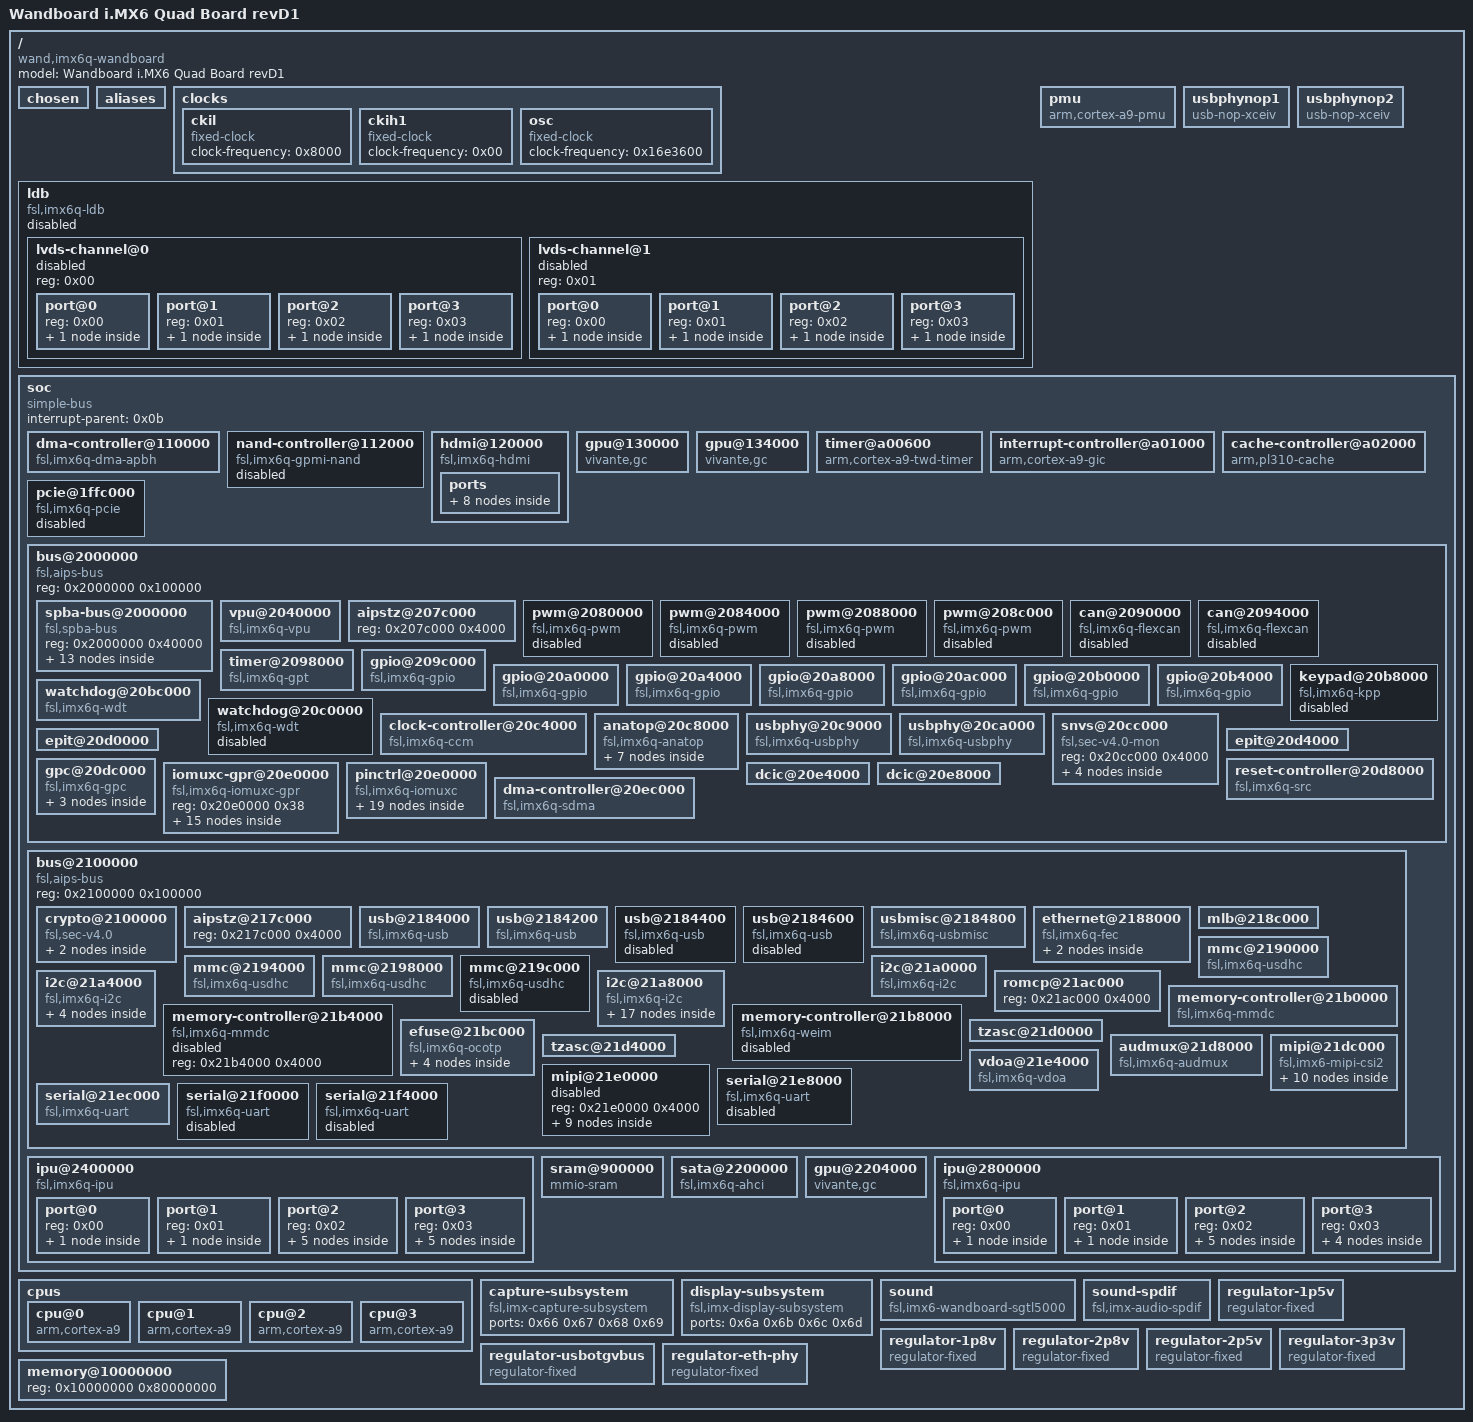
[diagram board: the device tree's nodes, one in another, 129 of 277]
/*
 * Copyright Linux Kernel Team
 *
 * SPDX-License-Identifier: GPL-2.0-only
 *
 * This file is derived from an intermediate build stage of the
 * Linux kernel. The licenses of all input files to this process
 * are compatible with GPL-2.0-only.
 */

/dts-v1/;

/ {
	#address-cells = <0x01>;
	#size-cells = <0x01>;
	model = "Wandboard i.MX6 Quad Board revD1";
	compatible = "wand,imx6q-wandboard", "fsl,imx6q";

	chosen {
		stdout-path = "/soc/bus@2000000/spba-bus@2000000/serial@2020000";
	};

	aliases {
		ethernet0 = "/soc/bus@2100000/ethernet@2188000";
		can0 = "/soc/bus@2000000/can@2090000";
		can1 = "/soc/bus@2000000/can@2094000";
		gpio0 = "/soc/bus@2000000/gpio@209c000";
		gpio1 = "/soc/bus@2000000/gpio@20a0000";
		gpio2 = "/soc/bus@2000000/gpio@20a4000";
		gpio3 = "/soc/bus@2000000/gpio@20a8000";
		gpio4 = "/soc/bus@2000000/gpio@20ac000";
		gpio5 = "/soc/bus@2000000/gpio@20b0000";
		gpio6 = "/soc/bus@2000000/gpio@20b4000";
		i2c0 = "/soc/bus@2100000/i2c@21a0000";
		i2c1 = "/soc/bus@2100000/i2c@21a4000";
		i2c2 = "/soc/bus@2100000/i2c@21a8000";
		ipu0 = "/soc/ipu@2400000";
		mmc0 = "/soc/bus@2100000/mmc@2190000";
		mmc1 = "/soc/bus@2100000/mmc@2194000";
		mmc2 = "/soc/bus@2100000/mmc@2198000";
		mmc3 = "/soc/bus@2100000/mmc@219c000";
		serial0 = "/soc/bus@2000000/spba-bus@2000000/serial@2020000";
		serial1 = "/soc/bus@2100000/serial@21e8000";
		serial2 = "/soc/bus@2100000/serial@21ec000";
		serial3 = "/soc/bus@2100000/serial@21f0000";
		serial4 = "/soc/bus@2100000/serial@21f4000";
		spi0 = "/soc/bus@2000000/spba-bus@2000000/spi@2008000";
		spi1 = "/soc/bus@2000000/spba-bus@2000000/spi@200c000";
		spi2 = "/soc/bus@2000000/spba-bus@2000000/spi@2010000";
		spi3 = "/soc/bus@2000000/spba-bus@2000000/spi@2014000";
		usb0 = "/soc/bus@2100000/usb@2184000";
		usb1 = "/soc/bus@2100000/usb@2184200";
		usb2 = "/soc/bus@2100000/usb@2184400";
		usb3 = "/soc/bus@2100000/usb@2184600";
		usbphy0 = "/soc/bus@2000000/usbphy@20c9000";
		usbphy1 = "/soc/bus@2000000/usbphy@20ca000";
		ipu1 = "/soc/ipu@2800000";
		spi4 = "/soc/bus@2000000/spba-bus@2000000/spi@2018000";
	};

	clocks {

		ckil {
			compatible = "fixed-clock";
			#clock-cells = <0x00>;
			clock-frequency = <0x8000>;
		};

		ckih1 {
			compatible = "fixed-clock";
			#clock-cells = <0x00>;
			clock-frequency = <0x00>;
		};

		osc {
			compatible = "fixed-clock";
			#clock-cells = <0x00>;
			clock-frequency = <0x16e3600>;
		};
	};

	ldb {
		#address-cells = <0x01>;
		#size-cells = <0x00>;
		compatible = "fsl,imx6q-ldb", "fsl,imx53-ldb";
		gpr = <0x01>;
		status = "disabled";
		clocks = <0x02 0x21 0x02 0x22 0x02 0x27 0x02 0x28 0x02 0x29 0x02 0x2a 0x02 0x87 0x02 0x88>;
		clock-names = "di0_pll", "di1_pll", "di0_sel", "di1_sel", "di2_sel", "di3_sel", "di0", "di1";

		lvds-channel@0 {
			#address-cells = <0x01>;
			#size-cells = <0x00>;
			reg = <0x00>;
			status = "disabled";

			port@0 {
				reg = <0x00>;

				endpoint {
					remote-endpoint = <0x03>;
					phandle = <0x52>;
				};
			};

			port@1 {
				reg = <0x01>;

				endpoint {
					remote-endpoint = <0x04>;
					phandle = <0x56>;
				};
			};

			port@2 {
				reg = <0x02>;

				endpoint {
					remote-endpoint = <0x05>;
					phandle = <0x5c>;
				};
			};

			port@3 {
				reg = <0x03>;

				endpoint {
					remote-endpoint = <0x06>;
					phandle = <0x60>;
				};
			};
		};

		lvds-channel@1 {
			#address-cells = <0x01>;
			#size-cells = <0x00>;
			reg = <0x01>;
			status = "disabled";

			port@0 {
				reg = <0x00>;

				endpoint {
					remote-endpoint = <0x07>;
					phandle = <0x53>;
				};
			};

			port@1 {
				reg = <0x01>;

				endpoint {
					remote-endpoint = <0x08>;
					phandle = <0x57>;
				};
			};

			port@2 {
				reg = <0x02>;

				endpoint {
					remote-endpoint = <0x09>;
					phandle = <0x5d>;
				};
			};

			port@3 {
				reg = <0x03>;

				endpoint {
					remote-endpoint = <0x0a>;
					phandle = <0x61>;
				};
			};
		};
	};

	pmu {
		compatible = "arm,cortex-a9-pmu";
		interrupt-parent = <0x0b>;
		interrupts = <0x00 0x5e 0x04>;
	};

	usbphynop1 {
		compatible = "usb-nop-xceiv";
		#phy-cells = <0x00>;
		phandle = <0x2a>;
	};

	usbphynop2 {
		compatible = "usb-nop-xceiv";
		#phy-cells = <0x00>;
		phandle = <0x2b>;
	};

	soc {
		#address-cells = <0x01>;
		#size-cells = <0x01>;
		compatible = "simple-bus";
		interrupt-parent = <0x0b>;
		ranges;

		dma-controller@110000 {
			compatible = "fsl,imx6q-dma-apbh", "fsl,imx28-dma-apbh";
			reg = <0x110000 0x2000>;
			interrupts = <0x00 0x0d 0x04 0x00 0x0d 0x04 0x00 0x0d 0x04 0x00 0x0d 0x04>;
			#dma-cells = <0x01>;
			dma-channels = <0x04>;
			clocks = <0x02 0x6a>;
			phandle = <0x0c>;
		};

		nand-controller@112000 {
			compatible = "fsl,imx6q-gpmi-nand";
			reg = <0x112000 0x2000 0x114000 0x2000>;
			reg-names = "gpmi-nand", "bch";
			interrupts = <0x00 0x0f 0x04>;
			interrupt-names = "bch";
			clocks = <0x02 0x98 0x02 0x99 0x02 0x97 0x02 0x96 0x02 0x95>;
			clock-names = "gpmi_io", "gpmi_apb", "gpmi_bch", "gpmi_bch_apb", "per1_bch";
			dmas = <0x0c 0x00>;
			dma-names = "rx-tx";
			status = "disabled";
		};

		hdmi@120000 {
			reg = <0x120000 0x9000>;
			interrupts = <0x00 0x73 0x04>;
			gpr = <0x01>;
			clocks = <0x02 0x7b 0x02 0x7c>;
			clock-names = "iahb", "isfr";
			status = "okay";
			compatible = "fsl,imx6q-hdmi";
			ddc-i2c-bus = <0x0d>;

			ports {
				#address-cells = <0x01>;
				#size-cells = <0x00>;

				port@0 {
					reg = <0x00>;

					endpoint {
						remote-endpoint = <0x0e>;
						phandle = <0x50>;
					};
				};

				port@1 {
					reg = <0x01>;

					endpoint {
						remote-endpoint = <0x0f>;
						phandle = <0x54>;
					};
				};

				port@2 {
					reg = <0x02>;

					endpoint {
						remote-endpoint = <0x10>;
						phandle = <0x5a>;
					};
				};

				port@3 {
					reg = <0x03>;

					endpoint {
						remote-endpoint = <0x11>;
						phandle = <0x5e>;
					};
				};
			};
		};

		gpu@130000 {
			compatible = "vivante,gc";
			reg = <0x130000 0x4000>;
			interrupts = <0x00 0x09 0x04>;
			clocks = <0x02 0x1b 0x02 0x7a 0x02 0x4a>;
			clock-names = "bus", "core", "shader";
			power-domains = <0x12>;
			#cooling-cells = <0x02>;
		};

		gpu@134000 {
			compatible = "vivante,gc";
			reg = <0x134000 0x4000>;
			interrupts = <0x00 0x0a 0x04>;
			clocks = <0x02 0x1a 0x02 0x79>;
			clock-names = "bus", "core";
			power-domains = <0x12>;
			#cooling-cells = <0x02>;
		};

		timer@a00600 {
			compatible = "arm,cortex-a9-twd-timer";
			reg = <0xa00600 0x20>;
			interrupts = <0x01 0x0d 0xf01>;
			interrupt-parent = <0x13>;
			clocks = <0x02 0x0f>;
		};

		interrupt-controller@a01000 {
			compatible = "arm,cortex-a9-gic";
			#interrupt-cells = <0x03>;
			interrupt-controller;
			reg = <0xa01000 0x1000 0xa00100 0x100>;
			interrupt-parent = <0x13>;
			phandle = <0x13>;
		};

		cache-controller@a02000 {
			compatible = "arm,pl310-cache";
			reg = <0xa02000 0x1000>;
			interrupts = <0x00 0x5c 0x04>;
			cache-unified;
			cache-level = <0x02>;
			arm,tag-latency = <0x04 0x02 0x03>;
			arm,data-latency = <0x04 0x02 0x03>;
			arm,shared-override;
			phandle = <0x62>;
		};

		pcie@1ffc000 {
			compatible = "fsl,imx6q-pcie";
			reg = <0x1ffc000 0x4000 0x1f00000 0x80000>;
			reg-names = "dbi", "config";
			#address-cells = <0x03>;
			#size-cells = <0x02>;
			device_type = "pci";
			bus-range = <0x00 0xff>;
			ranges = <0x81000000 0x00 0x00 0x1f80000 0x00 0x10000 0x82000000 0x00 0x1000000 0x1000000 0x00 0xf00000>;
			num-lanes = <0x01>;
			interrupts = <0x00 0x78 0x04>;
			interrupt-names = "msi";
			#interrupt-cells = <0x01>;
			interrupt-map-mask = <0x00 0x00 0x00 0x07>;
			interrupt-map = <0x00 0x00 0x00 0x01 0x0b 0x00 0x7b 0x04 0x00 0x00 0x00 0x02 0x0b 0x00 0x7a 0x04 0x00 0x00 0x00 0x03 0x0b 0x00 0x79 0x04 0x00 0x00 0x00 0x04 0x0b 0x00 0x78 0x04>;
			clocks = <0x02 0x90 0x02 0xce 0x02 0xbd>;
			clock-names = "pcie", "pcie_bus", "pcie_phy";
			status = "disabled";
		};

		bus@2000000 {
			compatible = "fsl,aips-bus", "simple-bus";
			#address-cells = <0x01>;
			#size-cells = <0x01>;
			reg = <0x2000000 0x100000>;
			ranges;

			spba-bus@2000000 {
				compatible = "fsl,spba-bus", "simple-bus";
				#address-cells = <0x01>;
				#size-cells = <0x01>;
				reg = <0x2000000 0x40000>;
				ranges;

				spdif@2004000 {
					compatible = "fsl,imx35-spdif";
					reg = <0x2004000 0x4000>;
					interrupts = <0x00 0x34 0x04>;
					dmas = <0x14 0x0e 0x12 0x00 0x14 0x0f 0x12 0x00>;
					dma-names = "rx", "tx";
					clocks = <0x02 0xf4 0x02 0x03 0x02 0xc5 0x02 0x6b 0x02 0x00 0x02 0x76 0x02 0x3e 0x02 0x00 0x02 0x00 0x02 0x9c>;
					clock-names = "core", "rxtx0", "rxtx1", "rxtx2", "rxtx3", "rxtx4", "rxtx5", "rxtx6", "rxtx7", "spba";
					status = "okay";
					pinctrl-names = "default";
					pinctrl-0 = <0x15>;
					phandle = <0x70>;
				};

				spi@2008000 {
					#address-cells = <0x01>;
					#size-cells = <0x00>;
					compatible = "fsl,imx6q-ecspi", "fsl,imx51-ecspi";
					reg = <0x2008000 0x4000>;
					interrupts = <0x00 0x1f 0x04>;
					clocks = <0x02 0x70 0x02 0x70>;
					clock-names = "ipg", "per";
					dmas = <0x14 0x03 0x07 0x01 0x14 0x04 0x07 0x02>;
					dma-names = "rx", "tx";
					status = "disabled";
				};

				spi@200c000 {
					#address-cells = <0x01>;
					#size-cells = <0x00>;
					compatible = "fsl,imx6q-ecspi", "fsl,imx51-ecspi";
					reg = <0x200c000 0x4000>;
					interrupts = <0x00 0x20 0x04>;
					clocks = <0x02 0x71 0x02 0x71>;
					clock-names = "ipg", "per";
					dmas = <0x14 0x05 0x07 0x01 0x14 0x06 0x07 0x02>;
					dma-names = "rx", "tx";
					status = "disabled";
				};

				spi@2010000 {
					#address-cells = <0x01>;
					#size-cells = <0x00>;
					compatible = "fsl,imx6q-ecspi", "fsl,imx51-ecspi";
					reg = <0x2010000 0x4000>;
					interrupts = <0x00 0x21 0x04>;
					clocks = <0x02 0x72 0x02 0x72>;
					clock-names = "ipg", "per";
					dmas = <0x14 0x07 0x07 0x01 0x14 0x08 0x07 0x02>;
					dma-names = "rx", "tx";
					status = "disabled";
				};

				spi@2014000 {
					#address-cells = <0x01>;
					#size-cells = <0x00>;
					compatible = "fsl,imx6q-ecspi", "fsl,imx51-ecspi";
					reg = <0x2014000 0x4000>;
					interrupts = <0x00 0x22 0x04>;
					clocks = <0x02 0x73 0x02 0x73>;
					clock-names = "ipg", "per";
					dmas = <0x14 0x09 0x07 0x01 0x14 0x0a 0x07 0x02>;
					dma-names = "rx", "tx";
					status = "disabled";
				};

				serial@2020000 {
					compatible = "fsl,imx6q-uart", "fsl,imx21-uart";
					reg = <0x2020000 0x4000>;
					interrupts = <0x00 0x1a 0x04>;
					clocks = <0x02 0xa0 0x02 0xa1>;
					clock-names = "ipg", "per";
					dmas = <0x14 0x19 0x04 0x00 0x14 0x1a 0x04 0x00>;
					dma-names = "rx", "tx";
					status = "okay";
					pinctrl-names = "default";
					pinctrl-0 = <0x16>;
				};

				esai@2024000 {
					#sound-dai-cells = <0x00>;
					compatible = "fsl,imx35-esai";
					reg = <0x2024000 0x4000>;
					interrupts = <0x00 0x33 0x04>;
					clocks = <0x02 0xd0 0x02 0x76 0x02 0xd0 0x02 0x9c>;
					clock-names = "core", "extal", "fsys", "spba";
					dmas = <0x14 0x17 0x15 0x00 0x14 0x18 0x15 0x00>;
					dma-names = "rx", "tx";
					status = "disabled";
				};

				ssi@2028000 {
					#sound-dai-cells = <0x00>;
					compatible = "fsl,imx6q-ssi", "fsl,imx51-ssi";
					reg = <0x2028000 0x4000>;
					interrupts = <0x00 0x2e 0x04>;
					clocks = <0x02 0xb2 0x02 0x9d>;
					clock-names = "ipg", "baud";
					dmas = <0x14 0x25 0x01 0x00 0x14 0x26 0x01 0x00>;
					dma-names = "rx", "tx";
					fsl,fifo-depth = <0x0f>;
					status = "okay";
					phandle = <0x6e>;
				};

				ssi@202c000 {
					#sound-dai-cells = <0x00>;
					compatible = "fsl,imx6q-ssi", "fsl,imx51-ssi";
					reg = <0x202c000 0x4000>;
					interrupts = <0x00 0x2f 0x04>;
					clocks = <0x02 0xb3 0x02 0x9e>;
					clock-names = "ipg", "baud";
					dmas = <0x14 0x29 0x01 0x00 0x14 0x2a 0x01 0x00>;
					dma-names = "rx", "tx";
					fsl,fifo-depth = <0x0f>;
					status = "disabled";
				};

				ssi@2030000 {
					#sound-dai-cells = <0x00>;
					compatible = "fsl,imx6q-ssi", "fsl,imx51-ssi";
					reg = <0x2030000 0x4000>;
					interrupts = <0x00 0x30 0x04>;
					clocks = <0x02 0xb4 0x02 0x9f>;
					clock-names = "ipg", "baud";
					dmas = <0x14 0x2d 0x01 0x00 0x14 0x2e 0x01 0x00>;
					dma-names = "rx", "tx";
					fsl,fifo-depth = <0x0f>;
					status = "disabled";
				};

				asrc@2034000 {
					compatible = "fsl,imx53-asrc";
					reg = <0x2034000 0x4000>;
					interrupts = <0x00 0x32 0x04>;
					clocks = <0x02 0xd2 0x02 0xd3 0x02 0x00 0x02 0x00 0x02 0x00 0x02 0x00 0x02 0x00 0x02 0x00 0x02 0x00 0x02 0x00 0x02 0x00 0x02 0x00 0x02 0x00 0x02 0x00 0x02 0x00 0x02 0x6b 0x02 0x00 0x02 0x00 0x02 0x9c>;
					clock-names = "mem", "ipg", "asrck_0", "asrck_1", "asrck_2", "asrck_3", "asrck_4", "asrck_5", "asrck_6", "asrck_7", "asrck_8", "asrck_9", "asrck_a", "asrck_b", "asrck_c", "asrck_d", "asrck_e", "asrck_f", "spba";
					dmas = <0x14 0x11 0x17 0x01 0x14 0x12 0x17 0x01 0x14 0x13 0x17 0x01 0x14 0x14 0x17 0x01 0x14 0x15 0x17 0x01 0x14 0x16 0x17 0x01>;
					dma-names = "rxa", "rxb", "rxc", "txa", "txb", "txc";
					fsl,asrc-rate = <0xbb80>;
					fsl,asrc-width = <0x10>;
					status = "okay";
				};

				spba-bus@203c000 {
					reg = <0x203c000 0x4000>;
				};

				spi@2018000 {
					#address-cells = <0x01>;
					#size-cells = <0x00>;
					compatible = "fsl,imx6q-ecspi", "fsl,imx51-ecspi";
					reg = <0x2018000 0x4000>;
					interrupts = <0x00 0x23 0x04>;
					clocks = <0x02 0x74 0x02 0x74>;
					clock-names = "ipg", "per";
					dmas = <0x14 0x0b 0x07 0x01 0x14 0x0c 0x07 0x02>;
					dma-names = "rx", "tx";
					status = "disabled";
				};
			};

			vpu@2040000 {
				compatible = "fsl,imx6q-vpu", "cnm,coda960";
				reg = <0x2040000 0x3c000>;
				interrupts = <0x00 0x0c 0x04 0x00 0x03 0x04>;
				interrupt-names = "bit", "jpeg";
				clocks = <0x02 0xa8 0x02 0x8c>;
				clock-names = "per", "ahb";
				power-domains = <0x12>;
				resets = <0x17 0x01>;
				iram = <0x18>;
			};

			aipstz@207c000 {
				reg = <0x207c000 0x4000>;
			};

			pwm@2080000 {
				#pwm-cells = <0x03>;
				compatible = "fsl,imx6q-pwm", "fsl,imx27-pwm";
				reg = <0x2080000 0x4000>;
				interrupts = <0x00 0x53 0x04>;
				clocks = <0x02 0x3e 0x02 0x91>;
				clock-names = "ipg", "per";
				status = "disabled";
			};

			pwm@2084000 {
				#pwm-cells = <0x03>;
				compatible = "fsl,imx6q-pwm", "fsl,imx27-pwm";
				reg = <0x2084000 0x4000>;
				interrupts = <0x00 0x54 0x04>;
				clocks = <0x02 0x3e 0x02 0x92>;
				clock-names = "ipg", "per";
				status = "disabled";
			};

			pwm@2088000 {
				#pwm-cells = <0x03>;
				compatible = "fsl,imx6q-pwm", "fsl,imx27-pwm";
				reg = <0x2088000 0x4000>;
				interrupts = <0x00 0x55 0x04>;
				clocks = <0x02 0x3e 0x02 0x93>;
				clock-names = "ipg", "per";
				status = "disabled";
			};

			pwm@208c000 {
				#pwm-cells = <0x03>;
				compatible = "fsl,imx6q-pwm", "fsl,imx27-pwm";
				reg = <0x208c000 0x4000>;
				interrupts = <0x00 0x56 0x04>;
				clocks = <0x02 0x3e 0x02 0x94>;
				clock-names = "ipg", "per";
				status = "disabled";
			};

			can@2090000 {
				compatible = "fsl,imx6q-flexcan";
				reg = <0x2090000 0x4000>;
				interrupts = <0x00 0x6e 0x04>;
				clocks = <0x02 0x6c 0x02 0x6d>;
				clock-names = "ipg", "per";
				fsl,stop-mode = <0x01 0x34 0x1c>;
				status = "disabled";
			};

			can@2094000 {
				compatible = "fsl,imx6q-flexcan";
				reg = <0x2094000 0x4000>;
				interrupts = <0x00 0x6f 0x04>;
				clocks = <0x02 0x6e 0x02 0x6f>;
				clock-names = "ipg", "per";
				fsl,stop-mode = <0x01 0x34 0x1d>;
				status = "disabled";
			};

			timer@2098000 {
				compatible = "fsl,imx6q-gpt", "fsl,imx31-gpt";
				reg = <0x2098000 0x4000>;
				interrupts = <0x00 0x37 0x04>;
				clocks = <0x02 0x77 0x02 0x78 0x02 0xed>;
				clock-names = "ipg", "per", "osc_per";
			};

			gpio@209c000 {
				compatible = "fsl,imx6q-gpio", "fsl,imx35-gpio";
				reg = <0x209c000 0x4000>;
				interrupts = <0x00 0x42 0x04 0x00 0x43 0x04>;
				gpio-controller;
				#gpio-cells = <0x02>;
				interrupt-controller;
				#interrupt-cells = <0x02>;
				gpio-ranges = <0x19 0x00 0x88 0x02 0x19 0x02 0x8d 0x01 0x19 0x03 0x8b 0x01 0x19 0x04 0x8e 0x02 0x19 0x06 0x8c 0x01 0x19 0x07 0x90 0x02 0x19 0x09 0x8a 0x01 0x19 0x0a 0xd5 0x03 0x19 0x0d 0x14 0x01 0x19 0x0e 0x13 0x01 0x19 0x0f 0x15 0x01 0x19 0x10 0xd0 0x01 0x19 0x11 0xcf 0x01 0x19 0x12 0xd2 0x03 0x19 0x15 0xd1 0x01 0x19 0x16 0x74 0x0a>;
				phandle = <0x32>;
			};

			gpio@20a0000 {
				compatible = "fsl,imx6q-gpio", "fsl,imx35-gpio";
				reg = <0x20a0000 0x4000>;
				interrupts = <0x00 0x44 0x04 0x00 0x45 0x04>;
				gpio-controller;
				#gpio-cells = <0x02>;
				interrupt-controller;
				#interrupt-cells = <0x02>;
				gpio-ranges = <0x19 0x00 0xbf 0x10 0x19 0x10 0x37 0x0e 0x19 0x1e 0x23 0x01 0x19 0x1f 0x2c 0x01>;
			};

			gpio@20a4000 {
				compatible = "fsl,imx6q-gpio", "fsl,imx35-gpio";
				reg = <0x20a4000 0x4000>;
				interrupts = <0x00 0x46 0x04 0x00 0x47 0x04>;
				gpio-controller;
				#gpio-cells = <0x02>;
				interrupt-controller;
				#interrupt-cells = <0x02>;
				gpio-ranges = <0x19 0x00 0x45 0x10 0x19 0x10 0x24 0x08 0x19 0x18 0x2d 0x08>;
				phandle = <0x2f>;
			};

			gpio@20a8000 {
				compatible = "fsl,imx6q-gpio", "fsl,imx35-gpio";
				reg = <0x20a8000 0x4000>;
				interrupts = <0x00 0x48 0x04 0x00 0x49 0x04>;
				gpio-controller;
				#gpio-cells = <0x02>;
				interrupt-controller;
				#interrupt-cells = <0x02>;
				gpio-ranges = <0x19 0x05 0x95 0x01 0x19 0x06 0x7e 0x0a 0x19 0x10 0x57 0x10>;
				phandle = <0x39>;
			};

			gpio@20ac000 {
				compatible = "fsl,imx6q-gpio", "fsl,imx35-gpio";
				reg = <0x20ac000 0x4000>;
				interrupts = <0x00 0x4a 0x04 0x00 0x4b 0x04>;
				gpio-controller;
				#gpio-cells = <0x02>;
				interrupt-controller;
				#interrupt-cells = <0x02>;
				gpio-ranges = <0x19 0x00 0x55 0x01 0x19 0x02 0x22 0x01 0x19 0x04 0x35 0x01 0x19 0x05 0x67 0x0d 0x19 0x12 0x96 0x0e>;
			};

			gpio@20b0000 {
				compatible = "fsl,imx6q-gpio", "fsl,imx35-gpio";
				reg = <0x20b0000 0x4000>;
				interrupts = <0x00 0x4c 0x04 0x00 0x4d 0x04>;
				gpio-controller;
				#gpio-cells = <0x02>;
				interrupt-controller;
				#interrupt-cells = <0x02>;
				gpio-ranges = <0x19 0x00 0xa4 0x06 0x19 0x06 0x36 0x01 0x19 0x07 0xb5 0x05 0x19 0x0e 0xba 0x03 0x19 0x11 0xaa 0x02 0x19 0x13 0x16 0x0c 0x19 0x1f 0x56 0x01>;
			};

			gpio@20b4000 {
				compatible = "fsl,imx6q-gpio", "fsl,imx35-gpio";
				reg = <0x20b4000 0x4000>;
				interrupts = <0x00 0x4e 0x04 0x00 0x4f 0x04>;
				gpio-controller;
				#gpio-cells = <0x02>;
				interrupt-controller;
				#interrupt-cells = <0x02>;
				gpio-ranges = <0x19 0x00 0xac 0x09 0x19 0x09 0xbd 0x02 0x19 0x0b 0x92 0x03>;
				phandle = <0x72>;
			};

			keypad@20b8000 {
				compatible = "fsl,imx6q-kpp", "fsl,imx21-kpp";
				reg = <0x20b8000 0x4000>;
				interrupts = <0x00 0x52 0x04>;
				clocks = <0x02 0x3e>;
				status = "disabled";
			};

			watchdog@20bc000 {
				compatible = "fsl,imx6q-wdt", "fsl,imx21-wdt";
				reg = <0x20bc000 0x4000>;
				interrupts = <0x00 0x50 0x04>;
				clocks = <0x02 0x3e>;
			};

			watchdog@20c0000 {
				compatible = "fsl,imx6q-wdt", "fsl,imx21-wdt";
				reg = <0x20c0000 0x4000>;
				interrupts = <0x00 0x51 0x04>;
				clocks = <0x02 0x3e>;
				status = "disabled";
			};

			clock-controller@20c4000 {
				compatible = "fsl,imx6q-ccm";
				reg = <0x20c4000 0x4000>;
				interrupts = <0x00 0x57 0x04 0x00 0x58 0x04>;
				#clock-cells = <0x01>;
				phandle = <0x02>;
			};

			anatop@20c8000 {
				compatible = "fsl,imx6q-anatop", "syscon", "simple-mfd";
				reg = <0x20c8000 0x1000>;
				interrupts = <0x00 0x31 0x04 0x00 0x36 0x04 0x00 0x7f 0x04>;
				phandle = <0x1a>;

				regulator-1p1 {
					compatible = "fsl,anatop-regulator";
					regulator-name = "vdd1p1";
					regulator-min-microvolt = <0xf4240>;
					regulator-max-microvolt = <0x124f80>;
					regulator-always-on;
					anatop-reg-offset = <0x110>;
					anatop-vol-bit-shift = <0x08>;
					anatop-vol-bit-width = <0x05>;
					anatop-min-bit-val = <0x04>;
					anatop-min-voltage = "", "\f5";
					anatop-max-voltage = <0x14fb18>;
					anatop-enable-bit = <0x00>;
				};

				regulator-3p0 {
					compatible = "fsl,anatop-regulator";
					regulator-name = "vdd3p0";
					regulator-min-microvolt = <0x2ab980>;
					regulator-max-microvolt = <0x3010b0>;
					regulator-always-on;
					anatop-reg-offset = <0x120>;
					anatop-vol-bit-shift = <0x08>;
					anatop-vol-bit-width = <0x05>;
					anatop-min-bit-val = <0x00>;
					anatop-min-voltage = <0x280de8>;
					anatop-max-voltage = <0x33e140>;
					anatop-enable-bit = <0x00>;
				};

				regulator-2p5 {
					compatible = "fsl,anatop-regulator";
					regulator-name = "vdd2p5";
					regulator-min-microvolt = <0x225510>;
					regulator-max-microvolt = <0x29f630>;
					regulator-always-on;
					anatop-reg-offset = <0x130>;
					anatop-vol-bit-shift = <0x08>;
					anatop-vol-bit-width = <0x05>;
					anatop-min-bit-val = <0x00>;
					anatop-min-voltage = <0x200b20>;
					anatop-max-voltage = <0x2bde78>;
					anatop-enable-bit = <0x00>;
				};

				regulator-vddcore {
					compatible = "fsl,anatop-regulator";
					regulator-name = "vddarm";
					regulator-min-microvolt = <0xb1008>;
					regulator-max-microvolt = <0x162010>;
					regulator-always-on;
					anatop-reg-offset = <0x140>;
					anatop-vol-bit-shift = <0x00>;
					anatop-vol-bit-width = <0x05>;
					anatop-delay-reg-offset = <0x170>;
					anatop-delay-bit-shift = <0x18>;
					anatop-delay-bit-width = <0x02>;
					anatop-min-bit-val = <0x01>;
					anatop-min-voltage = <0xb1008>;
					anatop-max-voltage = <0x162010>;
					phandle = <0x63>;
				};

				regulator-vddpu {
					compatible = "fsl,anatop-regulator";
					regulator-name = "vddpu";
					regulator-min-microvolt = <0xb1008>;
					regulator-max-microvolt = <0x162010>;
					regulator-enable-ramp-delay = <0x17c>;
					anatop-reg-offset = <0x140>;
					anatop-vol-bit-shift = <0x09>;
					anatop-vol-bit-width = <0x05>;
					anatop-delay-reg-offset = <0x170>;
					anatop-delay-bit-shift = <0x1a>;
					anatop-delay-bit-width = <0x02>;
					anatop-min-bit-val = <0x01>;
					anatop-min-voltage = <0xb1008>;
					anatop-max-voltage = <0x162010>;
					phandle = <0x1e>;
				};

				regulator-vddsoc {
					compatible = "fsl,anatop-regulator";
					regulator-name = "vddsoc";
					regulator-min-microvolt = <0xb1008>;
					regulator-max-microvolt = <0x162010>;
					regulator-always-on;
					anatop-reg-offset = <0x140>;
					anatop-vol-bit-shift = <0x12>;
					anatop-vol-bit-width = <0x05>;
					anatop-delay-reg-offset = <0x170>;
					anatop-delay-bit-shift = <0x1c>;
					anatop-delay-bit-width = <0x02>;
					anatop-min-bit-val = <0x01>;
					anatop-min-voltage = <0xb1008>;
					anatop-max-voltage = <0x162010>;
					phandle = <0x64>;
				};

				tempmon {
					compatible = "fsl,imx6q-tempmon";
					interrupt-parent = <0x0b>;
					interrupts = <0x00 0x31 0x04>;
					fsl,tempmon = <0x1a>;
					nvmem-cells = <0x1b 0x1c>;
					nvmem-cell-names = "calib", "temp_grade";
					clocks = <0x02 0xac>;
					#thermal-sensor-cells = <0x00>;
				};
			};

			usbphy@20c9000 {
				compatible = "fsl,imx6q-usbphy", "fsl,imx23-usbphy";
				reg = <0x20c9000 0x1000>;
				interrupts = <0x00 0x2c 0x04>;
				clocks = <0x02 0xb6>;
				fsl,anatop = <0x1a>;
				phandle = <0x25>;
			};

			usbphy@20ca000 {
				compatible = "fsl,imx6q-usbphy", "fsl,imx23-usbphy";
				reg = <0x20ca000 0x1000>;
				interrupts = <0x00 0x2d 0x04>;
				clocks = <0x02 0xb7>;
				fsl,anatop = <0x1a>;
				phandle = <0x29>;
			};

			snvs@20cc000 {
				compatible = "fsl,sec-v4.0-mon", "syscon", "simple-mfd";
				reg = <0x20cc000 0x4000>;
				phandle = <0x1d>;

				snvs-rtc-lp {
					compatible = "fsl,sec-v4.0-mon-rtc-lp";
					regmap = <0x1d>;
					offset = <0x34>;
					interrupts = <0x00 0x13 0x04 0x00 0x14 0x04>;
				};

				snvs-poweroff {
					compatible = "syscon-poweroff";
					regmap = <0x1d>;
					offset = <0x38>;
					value = <0x60>;
					mask = <0x60>;
					status = "disabled";
				};

				snvs-powerkey {
					compatible = "fsl,sec-v4.0-pwrkey";
					regmap = <0x1d>;
					interrupts = <0x00 0x04 0x04>;
					linux,keycode = <0x74>;
					wakeup-source;
					status = "disabled";
				};

				snvs-lpgpr {
					compatible = "fsl,imx6q-snvs-lpgpr";
				};
			};

			epit@20d0000 {
				reg = <0x20d0000 0x4000>;
				interrupts = <0x00 0x38 0x04>;
			};

			epit@20d4000 {
				reg = <0x20d4000 0x4000>;
				interrupts = <0x00 0x39 0x04>;
			};

			reset-controller@20d8000 {
				compatible = "fsl,imx6q-src", "fsl,imx51-src";
				reg = <0x20d8000 0x4000>;
				interrupts = <0x00 0x5b 0x04 0x00 0x60 0x04>;
				#reset-cells = <0x01>;
				phandle = <0x17>;
			};

			gpc@20dc000 {
				compatible = "fsl,imx6q-gpc";
				reg = <0x20dc000 0x4000>;
				interrupt-controller;
				#interrupt-cells = <0x03>;
				interrupts = <0x00 0x59 0x04>;
				interrupt-parent = <0x13>;
				clocks = <0x02 0x3e>;
				clock-names = "ipg";
				phandle = <0x0b>;

				pgc {
					#address-cells = <0x01>;
					#size-cells = <0x00>;

					power-domain@0 {
						reg = <0x00>;
						#power-domain-cells = <0x00>;
					};

					power-domain@1 {
						reg = <0x01>;
						#power-domain-cells = <0x00>;
						power-supply = <0x1e>;
						clocks = <0x02 0x7a 0x02 0x4a 0x02 0x79 0x02 0x1a 0x02 0x8f 0x02 0xa8>;
						phandle = <0x12>;
					};
				};
			};

			iomuxc-gpr@20e0000 {
				compatible = "fsl,imx6q-iomuxc-gpr", "syscon", "simple-mfd";
				reg = <0x20e0000 0x38>;
				phandle = <0x01>;

				mux-controller {
					compatible = "mmio-mux";
					#mux-control-cells = <0x01>;
					mux-reg-masks = <0x04 0x80000 0x04 0x100000 0x0c 0x0c 0x0c 0xc0 0x0c 0x300 0x28 0x03 0x28 0x0c>;
					phandle = <0x1f>;
				};

				ipu1_csi0_mux {
					compatible = "video-mux";
					mux-controls = <0x1f 0x00>;
					#address-cells = <0x01>;
					#size-cells = <0x00>;

					port@0 {
						reg = <0x00>;

						endpoint {
							remote-endpoint = <0x20>;
							phandle = <0x44>;
						};
					};

					port@1 {
						reg = <0x01>;

						endpoint {
						};
					};

					port@2 {
						reg = <0x02>;

						endpoint {
							remote-endpoint = <0x21>;
							phandle = <0x4e>;
						};
					};
				};

				ipu2_csi1_mux {
					compatible = "video-mux";
					mux-controls = <0x1f 0x01>;
					#address-cells = <0x01>;
					#size-cells = <0x00>;

					port@0 {
						reg = <0x00>;

						endpoint {
							remote-endpoint = <0x22>;
							phandle = <0x47>;
						};
					};

					port@1 {
						reg = <0x01>;

						endpoint {
						};
					};

					port@2 {
						reg = <0x02>;

						endpoint {
							remote-endpoint = <0x23>;
							phandle = <0x59>;
						};
					};
				};
			};

			pinctrl@20e0000 {
				compatible = "fsl,imx6q-iomuxc";
				reg = <0x20e0000 0x4000>;
				pinctrl-names = "default";
				pinctrl-0 = <0x24>;
				phandle = <0x19>;

				imx6qdl-wandboard {

					audmuxgrp {
						fsl,pins = <0x274 0x644 0x00 0x04 0x00 0x130b0 0x268 0x638 0x00 0x04 0x00 0x130b0 0x26c 0x63c 0x00 0x04 0x00 0x110b0 0x270 0x640 0x00 0x04 0x00 0x130b0>;
						phandle = <0x43>;
					};

					enetgrp {
						fsl,pins = <0x1d0 0x4e4 0x840 0x01 0x00 0x1b0b0 0x1f4 0x508 0x00 0x01 0x00 0x1b0b0 0x58 0x36c 0x00 0x01 0x00 0x1b030 0x5c 0x370 0x00 0x01 0x00 0x1b030 0x60 0x374 0x00 0x01 0x00 0x1b030 0x64 0x378 0x00 0x01 0x00 0x1b030 0x68 0x37c 0x00 0x01 0x00 0x1b030 0x74 0x388 0x00 0x01 0x00 0x1b030 0x1d4 0x4e8 0x00 0x01 0x00 0x1b0b0 0x84 0x398 0x844 0x01 0x00 0x1b030 0x70 0x384 0x848 0x01 0x00 0x1b030 0x78 0x38c 0x84c 0x01 0x00 0x1b030 0x7c 0x390 0x850 0x01 0x00 0x1b030 0x80 0x394 0x854 0x01 0x00 0x1b030 0x6c 0x380 0x858 0x01 0x00 0x1b030>;
						phandle = <0x2d>;
					};

					i2c1grp {
						fsl,pins = <0xa4 0x3b8 0x898 0x06 0x00 0x4001b8b1 0xc4 0x3d8 0x89c 0x01 0x00 0x4001b8b1>;
						phandle = <0x35>;
					};

					i2c1gpiogrp {
						fsl,pins = <0xa4 0x3b8 0x00 0x05 0x00 0x4001b8b0 0xc4 0x3d8 0x00 0x05 0x00 0x4001b8b0>;
						phandle = <0x36>;
					};

					i2c2grp {
						fsl,pins = <0x210 0x5e0 0x8a0 0x04 0x01 0x4001b8b1 0x214 0x5e4 0x8a4 0x04 0x01 0x4001b8b1>;
						phandle = <0x37>;
					};

					i2c2gpiogrp {
						fsl,pins = <0x210 0x5e0 0x00 0x05 0x00 0x4001b8b0 0x214 0x5e4 0x00 0x05 0x00 0x4001b8b0>;
						phandle = <0x38>;
					};

					mclkgrp {
						fsl,pins = <0x220 0x5f0 0x00 0x00 0x00 0x130b0>;
						phandle = <0x3a>;
					};

					ov5645grp {
						fsl,pins = <0x22c 0x5fc 0x00 0x04 0x00 0xb0 0x230 0x600 0x00 0x05 0x00 0x1b0b0 0x218 0x5e8 0x00 0x05 0x00 0x1b0b0>;
						phandle = <0x3d>;
					};

					spdifgrp {
						fsl,pins = <0x254 0x624 0x00 0x02 0x00 0x1b0b0>;
						phandle = <0x15>;
					};

					uart1grp {
						fsl,pins = <0x280 0x650 0x00 0x03 0x00 0x1b0b1 0x284 0x654 0x920 0x03 0x01 0x1b0b1>;
						phandle = <0x16>;
					};

					uart3grp {
						fsl,pins = <0xb4 0x3c8 0x00 0x02 0x00 0x1b0b1 0xb8 0x3cc 0x930 0x02 0x01 0x1b0b1 0xac 0x3c0 0x00 0x02 0x00 0x1b0b1 0xb0 0x3c4 0x92c 0x02 0x01 0x1b0b1>;
						phandle = <0x4d>;
					};

					usbotggrp {
						fsl,pins = <0x224 0x5f4 0x04 0x03 0xff0d0101 0x17059>;
						phandle = <0x28>;
					};

					usbotgvbusgrp {
						fsl,pins = <0xa8 0x3bc 0x00 0x05 0x00 0x130b0>;
						phandle = <0x71>;
					};

					usdhc1grp {
						fsl,pins = <0x348 0x730 0x00 0x00 0x00 0x17059 0x350 0x738 0x00 0x00 0x00 0x10059 0x340 0x728 0x00 0x00 0x00 0x17059 0x33c 0x724 0x00 0x00 0x00 0x17059 0x34c 0x734 0x00 0x00 0x00 0x17059 0x344 0x72c 0x00 0x00 0x00 0x17059>;
						phandle = <0x31>;
					};

					usdhc2grp {
						fsl,pins = <0x358 0x740 0x00 0x00 0x00 0x17059 0x354 0x73c 0x00 0x00 0x00 0x10059 0x54 0x368 0x00 0x00 0x00 0x17059 0x4c 0x360 0x00 0x00 0x00 0x17059 0x50 0x364 0x00 0x00 0x00 0x17059 0x35c 0x744 0x00 0x00 0x00 0x17059>;
						phandle = <0x33>;
					};

					usdhc3grp {
						fsl,pins = <0x2b8 0x6a0 0x00 0x00 0x00 0x17059 0x2bc 0x6a4 0x00 0x00 0x00 0x10059 0x2c0 0x6a8 0x00 0x00 0x00 0x17059 0x2c4 0x6ac 0x00 0x00 0x00 0x17059 0x2c8 0x6b0 0x00 0x00 0x00 0x17059 0x2cc 0x6b4 0x00 0x00 0x00 0x17059>;
						phandle = <0x34>;
					};

					hoggrp {
						fsl,pins = <0x234 0x604 0x00 0x05 0x00 0x80000000 0x138 0x44c 0x00 0x05 0x00 0x80000000 0xc8 0x3dc 0x00 0x05 0x00 0x1f0b1>;
						phandle = <0x24>;
					};

					i2c3grp {
						fsl,pins = <0x23c 0x60c 0x8a8 0x06 0x02 0x4001b8b1 0x248 0x618 0x8ac 0x06 0x02 0x4001b8b1>;
						phandle = <0x42>;
					};
				};
			};

			dcic@20e4000 {
				reg = <0x20e4000 0x4000>;
				interrupts = <0x00 0x7c 0x04>;
			};

			dcic@20e8000 {
				reg = <0x20e8000 0x4000>;
				interrupts = <0x00 0x7d 0x04>;
			};

			dma-controller@20ec000 {
				compatible = "fsl,imx6q-sdma", "fsl,imx35-sdma";
				reg = <0x20ec000 0x4000>;
				interrupts = <0x00 0x02 0x04>;
				clocks = <0x02 0x3e 0x02 0x9b>;
				clock-names = "ipg", "ahb";
				#dma-cells = <0x03>;
				fsl,sdma-ram-script-name = "imx/sdma/sdma-imx6q.bin";
				phandle = <0x14>;
			};
		};

		bus@2100000 {
			compatible = "fsl,aips-bus", "simple-bus";
			#address-cells = <0x01>;
			#size-cells = <0x01>;
			reg = <0x2100000 0x100000>;
			ranges;

			crypto@2100000 {
				compatible = "fsl,sec-v4.0";
				#address-cells = <0x01>;
				#size-cells = <0x01>;
				reg = <0x2100000 0x10000>;
				ranges = <0x00 0x2100000 0x10000>;
				clocks = <0x02 0xf1 0x02 0xf2 0x02 0xf3 0x02 0xc4>;
				clock-names = "mem", "aclk", "ipg", "emi_slow";

				jr@1000 {
					compatible = "fsl,sec-v4.0-job-ring";
					reg = <0x1000 0x1000>;
					interrupts = <0x00 0x69 0x04>;
				};

				jr@2000 {
					compatible = "fsl,sec-v4.0-job-ring";
					reg = <0x2000 0x1000>;
					interrupts = <0x00 0x6a 0x04>;
				};
			};

			aipstz@217c000 {
				reg = <0x217c000 0x4000>;
			};

			usb@2184000 {
				compatible = "fsl,imx6q-usb", "fsl,imx27-usb";
				reg = <0x2184000 0x200>;
				interrupts = <0x00 0x2b 0x04>;
				clocks = <0x02 0xa2>;
				fsl,usbphy = <0x25>;
				fsl,usbmisc = <0x26 0x00>;
				ahb-burst-config = <0x00>;
				tx-burst-size-dword = <0x10>;
				rx-burst-size-dword = <0x10>;
				status = "okay";
				vbus-supply = <0x27>;
				pinctrl-names = "default";
				pinctrl-0 = <0x28>;
				disable-over-current;
				dr_mode = "otg";
			};

			usb@2184200 {
				compatible = "fsl,imx6q-usb", "fsl,imx27-usb";
				reg = <0x2184200 0x200>;
				interrupts = <0x00 0x28 0x04>;
				clocks = <0x02 0xa2>;
				fsl,usbphy = <0x29>;
				fsl,usbmisc = <0x26 0x01>;
				dr_mode = "host";
				ahb-burst-config = <0x00>;
				tx-burst-size-dword = <0x10>;
				rx-burst-size-dword = <0x10>;
				status = "okay";
			};

			usb@2184400 {
				compatible = "fsl,imx6q-usb", "fsl,imx27-usb";
				reg = <0x2184400 0x200>;
				interrupts = <0x00 0x29 0x04>;
				clocks = <0x02 0xa2>;
				fsl,usbphy = <0x2a>;
				phy_type = "hsic";
				fsl,usbmisc = <0x26 0x02>;
				dr_mode = "host";
				ahb-burst-config = <0x00>;
				tx-burst-size-dword = <0x10>;
				rx-burst-size-dword = <0x10>;
				status = "disabled";
			};

			usb@2184600 {
				compatible = "fsl,imx6q-usb", "fsl,imx27-usb";
				reg = <0x2184600 0x200>;
				interrupts = <0x00 0x2a 0x04>;
				clocks = <0x02 0xa2>;
				fsl,usbphy = <0x2b>;
				phy_type = "hsic";
				fsl,usbmisc = <0x26 0x03>;
				dr_mode = "host";
				ahb-burst-config = <0x00>;
				tx-burst-size-dword = <0x10>;
				rx-burst-size-dword = <0x10>;
				status = "disabled";
			};

			usbmisc@2184800 {
				#index-cells = <0x01>;
				compatible = "fsl,imx6q-usbmisc";
				reg = <0x2184800 0x200>;
				clocks = <0x02 0xa2>;
				phandle = <0x26>;
			};

			ethernet@2188000 {
				compatible = "fsl,imx6q-fec";
				reg = <0x2188000 0x4000>;
				interrupt-names = "int0", "pps";
				interrupts = <0x00 0x76 0x04 0x00 0x77 0x04>;
				clocks = <0x02 0x75 0x02 0x75 0x02 0xbe 0x02 0x10a>;
				clock-names = "ipg", "ahb", "ptp", "enet_clk_ref";
				fsl,stop-mode = <0x01 0x34 0x1b>;
				nvmem-cells = <0x2c>;
				nvmem-cell-names = "mac-address";
				status = "okay";
				pinctrl-names = "default";
				pinctrl-0 = <0x2d>;
				phy-mode = "rgmii-id";
				phy-handle = <0x2e>;
				phy-reset-gpios = <0x2f 0x1d 0x01>;
				phy-supply = <0x30>;

				mdio {
					#address-cells = <0x01>;
					#size-cells = <0x00>;

					ethernet-phy@1 {
						reg = <0x01>;
						qca,clk-out-frequency = <0x7735940>;
						phandle = <0x2e>;
					};
				};
			};

			mlb@218c000 {
				reg = <0x218c000 0x4000>;
				interrupts = <0x00 0x35 0x04 0x00 0x75 0x04 0x00 0x7e 0x04>;
			};

			mmc@2190000 {
				compatible = "fsl,imx6q-usdhc";
				reg = <0x2190000 0x4000>;
				interrupts = <0x00 0x16 0x04>;
				clocks = <0x02 0xa3 0x02 0xa3 0x02 0xa3>;
				clock-names = "ipg", "ahb", "per";
				bus-width = <0x04>;
				status = "okay";
				pinctrl-names = "default";
				pinctrl-0 = <0x31>;
				cd-gpios = <0x32 0x02 0x01>;
			};

			mmc@2194000 {
				compatible = "fsl,imx6q-usdhc";
				reg = <0x2194000 0x4000>;
				interrupts = <0x00 0x17 0x04>;
				clocks = <0x02 0xa4 0x02 0xa4 0x02 0xa4>;
				clock-names = "ipg", "ahb", "per";
				bus-width = <0x04>;
				status = "okay";
				pinctrl-names = "default";
				pinctrl-0 = <0x33>;
				no-1-8-v;
				non-removable;
			};

			mmc@2198000 {
				compatible = "fsl,imx6q-usdhc";
				reg = <0x2198000 0x4000>;
				interrupts = <0x00 0x18 0x04>;
				clocks = <0x02 0xa5 0x02 0xa5 0x02 0xa5>;
				clock-names = "ipg", "ahb", "per";
				bus-width = <0x04>;
				status = "okay";
				pinctrl-names = "default";
				pinctrl-0 = <0x34>;
				cd-gpios = <0x2f 0x09 0x01>;
			};

			mmc@219c000 {
				compatible = "fsl,imx6q-usdhc";
				reg = <0x219c000 0x4000>;
				interrupts = <0x00 0x19 0x04>;
				clocks = <0x02 0xa6 0x02 0xa6 0x02 0xa6>;
				clock-names = "ipg", "ahb", "per";
				bus-width = <0x04>;
				status = "disabled";
			};

			i2c@21a0000 {
				#address-cells = <0x01>;
				#size-cells = <0x00>;
				compatible = "fsl,imx6q-i2c", "fsl,imx21-i2c";
				reg = <0x21a0000 0x4000>;
				interrupts = <0x00 0x24 0x04>;
				clocks = <0x02 0x7d>;
				status = "okay";
				clock-frequency = <0x186a0>;
				pinctrl-names = "default", "gpio";
				pinctrl-0 = <0x35>;
				pinctrl-1 = <0x36>;
				scl-gpios = <0x2f 0x15 0x06>;
				sda-gpios = <0x2f 0x1c 0x06>;
			};

			i2c@21a4000 {
				#address-cells = <0x01>;
				#size-cells = <0x00>;
				compatible = "fsl,imx6q-i2c", "fsl,imx21-i2c";
				reg = <0x21a4000 0x4000>;
				interrupts = <0x00 0x25 0x04>;
				clocks = <0x02 0x7e>;
				status = "okay";
				clock-frequency = <0x186a0>;
				pinctrl-names = "default", "gpio";
				pinctrl-0 = <0x37>;
				pinctrl-1 = <0x38>;
				scl-gpios = <0x39 0x0c 0x06>;
				sda-gpios = <0x39 0x0d 0x06>;
				phandle = <0x0d>;

				sgtl5000@a {
					pinctrl-names = "default";
					pinctrl-0 = <0x3a>;
					compatible = "fsl,sgtl5000";
					reg = <0x0a>;
					#sound-dai-cells = <0x00>;
					clocks = <0x02 0xc9>;
					VDDA-supply = <0x3b>;
					VDDIO-supply = <0x3c>;
					lrclk-strength = <0x03>;
					phandle = <0x6f>;
				};

				camera@3c {
					compatible = "ovti,ov5645";
					pinctrl-names = "default";
					pinctrl-0 = <0x3d>;
					reg = <0x3c>;
					clocks = <0x02 0xc8>;
					clock-frequency = <0x16e3600>;
					vdddo-supply = <0x3e>;
					vdda-supply = <0x3f>;
					vddd-supply = <0x40>;
					enable-gpios = <0x32 0x06 0x00>;
					reset-gpios = <0x39 0x0e 0x01>;

					port {

						endpoint {
							remote-endpoint = <0x41>;
							clock-lanes = <0x00>;
							data-lanes = <0x01 0x02>;
							phandle = <0x48>;
						};
					};
				};
			};

			i2c@21a8000 {
				#address-cells = <0x01>;
				#size-cells = <0x00>;
				compatible = "fsl,imx6q-i2c", "fsl,imx21-i2c";
				reg = <0x21a8000 0x4000>;
				interrupts = <0x00 0x26 0x04>;
				clocks = <0x02 0x7f>;
				status = "okay";
				clock-frequency = <0x186a0>;
				pinctrl-names = "default";
				pinctrl-0 = <0x42>;

				pmic@8 {
					compatible = "fsl,pfuze100";
					reg = <0x08>;

					regulators {

						sw1ab {
							regulator-min-microvolt = <0x493e0>;
							regulator-max-microvolt = <0x1c9c38>;
							regulator-boot-on;
							regulator-always-on;
							regulator-ramp-delay = <0x186a>;
						};

						sw1c {
							regulator-min-microvolt = <0x493e0>;
							regulator-max-microvolt = <0x1c9c38>;
							regulator-boot-on;
							regulator-always-on;
							regulator-ramp-delay = <0x186a>;
						};

						sw2 {
							regulator-min-microvolt = "", "\f5";
							regulator-max-microvolt = <0x325aa0>;
							regulator-boot-on;
							regulator-always-on;
							regulator-ramp-delay = <0x186a>;
						};

						sw3a {
							regulator-min-microvolt = <0x61a80>;
							regulator-max-microvolt = <0x1e22d8>;
							regulator-boot-on;
							regulator-always-on;
						};

						sw3b {
							regulator-min-microvolt = <0x61a80>;
							regulator-max-microvolt = <0x1e22d8>;
							regulator-boot-on;
							regulator-always-on;
						};

						sw4 {
							regulator-min-microvolt = "", "\f5";
							regulator-max-microvolt = <0x325aa0>;
						};

						swbst {
							regulator-min-microvolt = <0x4c4b40>;
							regulator-max-microvolt = <0x4e9530>;
						};

						vsnvs {
							regulator-min-microvolt = <0xf4240>;
							regulator-max-microvolt = <0x2dc6c0>;
							regulator-boot-on;
							regulator-always-on;
						};

						vrefddr {
							regulator-boot-on;
							regulator-always-on;
						};

						vgen1 {
							regulator-min-microvolt = "", "\f5";
							regulator-max-microvolt = <0x17a6b0>;
						};

						vgen2 {
							regulator-min-microvolt = <0x16e360>;
							regulator-max-microvolt = <0x16e360>;
							regulator-boot-on;
							regulator-always-on;
						};

						vgen3 {
							regulator-min-microvolt = <0x1b7740>;
							regulator-max-microvolt = <0x325aa0>;
							regulator-always-on;
						};

						vgen4 {
							regulator-min-microvolt = <0x1b7740>;
							regulator-max-microvolt = <0x325aa0>;
							regulator-always-on;
						};

						vgen5 {
							regulator-min-microvolt = <0x1b7740>;
							regulator-max-microvolt = <0x325aa0>;
							regulator-always-on;
						};

						vgen6 {
							regulator-min-microvolt = <0x1b7740>;
							regulator-max-microvolt = <0x325aa0>;
							regulator-always-on;
						};
					};
				};
			};

			romcp@21ac000 {
				reg = <0x21ac000 0x4000>;
			};

			memory-controller@21b0000 {
				compatible = "fsl,imx6q-mmdc";
				reg = <0x21b0000 0x4000>;
				clocks = <0x02 0x107>;
			};

			memory-controller@21b4000 {
				compatible = "fsl,imx6q-mmdc";
				reg = <0x21b4000 0x4000>;
				status = "disabled";
			};

			memory-controller@21b8000 {
				#address-cells = <0x02>;
				#size-cells = <0x01>;
				compatible = "fsl,imx6q-weim";
				reg = <0x21b8000 0x4000>;
				interrupts = <0x00 0x0e 0x04>;
				clocks = <0x02 0xc4>;
				fsl,weim-cs-gpr = <0x01>;
				status = "disabled";
			};

			efuse@21bc000 {
				compatible = "fsl,imx6q-ocotp", "syscon";
				reg = <0x21bc000 0x4000>;
				clocks = <0x02 0x80>;
				#address-cells = <0x01>;
				#size-cells = <0x01>;

				speed-grade@10 {
					reg = <0x10 0x04>;
					phandle = <0x65>;
				};

				calib@38 {
					reg = <0x38 0x04>;
					phandle = <0x1b>;
				};

				temp-grade@20 {
					reg = <0x20 0x04>;
					phandle = <0x1c>;
				};

				mac-addr@88 {
					reg = <0x88 0x06>;
					phandle = <0x2c>;
				};
			};

			tzasc@21d0000 {
				reg = <0x21d0000 0x4000>;
				interrupts = <0x00 0x6c 0x04>;
			};

			tzasc@21d4000 {
				reg = <0x21d4000 0x4000>;
				interrupts = <0x00 0x6d 0x04>;
			};

			audmux@21d8000 {
				compatible = "fsl,imx6q-audmux", "fsl,imx31-audmux";
				reg = <0x21d8000 0x4000>;
				status = "okay";
				pinctrl-names = "default";
				pinctrl-0 = <0x43>;
			};

			mipi@21dc000 {
				compatible = "fsl,imx6-mipi-csi2";
				reg = <0x21dc000 0x4000>;
				#address-cells = <0x01>;
				#size-cells = <0x00>;
				interrupts = <0x00 0x64 0x04 0x00 0x65 0x04>;
				clocks = <0x02 0x8a 0x02 0xee 0x02 0x61>;
				clock-names = "dphy", "ref", "pix";
				status = "okay";

				port@1 {
					reg = <0x01>;

					endpoint {
						remote-endpoint = <0x44>;
						phandle = <0x20>;
					};
				};

				port@2 {
					reg = <0x02>;

					endpoint {
						remote-endpoint = <0x45>;
						phandle = <0x4f>;
					};
				};

				port@3 {
					reg = <0x03>;

					endpoint {
						remote-endpoint = <0x46>;
						phandle = <0x58>;
					};
				};

				port@4 {
					reg = <0x04>;

					endpoint {
						remote-endpoint = <0x47>;
						phandle = <0x22>;
					};
				};

				port@0 {
					reg = <0x00>;

					endpoint {
						remote-endpoint = <0x48>;
						clock-lanes = <0x00>;
						data-lanes = <0x01 0x02>;
						phandle = <0x41>;
					};
				};
			};

			mipi@21e0000 {
				reg = <0x21e0000 0x4000>;
				status = "disabled";

				ports {
					#address-cells = <0x01>;
					#size-cells = <0x00>;

					port@0 {
						reg = <0x00>;

						endpoint {
							remote-endpoint = <0x49>;
							phandle = <0x51>;
						};
					};

					port@1 {
						reg = <0x01>;

						endpoint {
							remote-endpoint = <0x4a>;
							phandle = <0x55>;
						};
					};

					port@2 {
						reg = <0x02>;

						endpoint {
							remote-endpoint = <0x4b>;
							phandle = <0x5b>;
						};
					};

					port@3 {
						reg = <0x03>;

						endpoint {
							remote-endpoint = <0x4c>;
							phandle = <0x5f>;
						};
					};
				};
			};

			vdoa@21e4000 {
				compatible = "fsl,imx6q-vdoa";
				reg = <0x21e4000 0x4000>;
				interrupts = <0x00 0x12 0x04>;
				clocks = <0x02 0xca>;
			};

			serial@21e8000 {
				compatible = "fsl,imx6q-uart", "fsl,imx21-uart";
				reg = <0x21e8000 0x4000>;
				interrupts = <0x00 0x1b 0x04>;
				clocks = <0x02 0xa0 0x02 0xa1>;
				clock-names = "ipg", "per";
				dmas = <0x14 0x1b 0x04 0x00 0x14 0x1c 0x04 0x00>;
				dma-names = "rx", "tx";
				status = "disabled";
			};

			serial@21ec000 {
				compatible = "fsl,imx6q-uart", "fsl,imx21-uart";
				reg = <0x21ec000 0x4000>;
				interrupts = <0x00 0x1c 0x04>;
				clocks = <0x02 0xa0 0x02 0xa1>;
				clock-names = "ipg", "per";
				dmas = <0x14 0x1d 0x04 0x00 0x14 0x1e 0x04 0x00>;
				dma-names = "rx", "tx";
				status = "okay";
				pinctrl-names = "default";
				pinctrl-0 = <0x4d>;
				uart-has-rtscts;
			};

			serial@21f0000 {
				compatible = "fsl,imx6q-uart", "fsl,imx21-uart";
				reg = <0x21f0000 0x4000>;
				interrupts = <0x00 0x1d 0x04>;
				clocks = <0x02 0xa0 0x02 0xa1>;
				clock-names = "ipg", "per";
				dmas = <0x14 0x1f 0x04 0x00 0x14 0x20 0x04 0x00>;
				dma-names = "rx", "tx";
				status = "disabled";
			};

			serial@21f4000 {
				compatible = "fsl,imx6q-uart", "fsl,imx21-uart";
				reg = <0x21f4000 0x4000>;
				interrupts = <0x00 0x1e 0x04>;
				clocks = <0x02 0xa0 0x02 0xa1>;
				clock-names = "ipg", "per";
				dmas = <0x14 0x21 0x04 0x00 0x14 0x22 0x04 0x00>;
				dma-names = "rx", "tx";
				status = "disabled";
			};
		};

		ipu@2400000 {
			#address-cells = <0x01>;
			#size-cells = <0x00>;
			compatible = "fsl,imx6q-ipu";
			reg = <0x2400000 0x400000>;
			interrupts = <0x00 0x06 0x04 0x00 0x05 0x04>;
			clocks = <0x02 0x82 0x02 0x83 0x02 0x84>;
			clock-names = "bus", "di0", "di1";
			resets = <0x17 0x02>;

			port@0 {
				reg = <0x00>;
				phandle = <0x66>;

				endpoint {
					remote-endpoint = <0x4e>;
					phandle = <0x21>;
				};
			};

			port@1 {
				reg = <0x01>;
				phandle = <0x67>;

				endpoint {
					remote-endpoint = <0x4f>;
					phandle = <0x45>;
				};
			};

			port@2 {
				#address-cells = <0x01>;
				#size-cells = <0x00>;
				reg = <0x02>;
				phandle = <0x6a>;

				endpoint@0 {
					reg = <0x00>;
				};

				endpoint@1 {
					reg = <0x01>;
					remote-endpoint = <0x50>;
					phandle = <0x0e>;
				};

				endpoint@2 {
					reg = <0x02>;
					remote-endpoint = <0x51>;
					phandle = <0x49>;
				};

				endpoint@3 {
					reg = <0x03>;
					remote-endpoint = <0x52>;
					phandle = <0x03>;
				};

				endpoint@4 {
					reg = <0x04>;
					remote-endpoint = <0x53>;
					phandle = <0x07>;
				};
			};

			port@3 {
				#address-cells = <0x01>;
				#size-cells = <0x00>;
				reg = <0x03>;
				phandle = <0x6b>;

				endpoint@0 {
					reg = <0x00>;
				};

				endpoint@1 {
					reg = <0x01>;
					remote-endpoint = <0x54>;
					phandle = <0x0f>;
				};

				endpoint@2 {
					reg = <0x02>;
					remote-endpoint = <0x55>;
					phandle = <0x4a>;
				};

				endpoint@3 {
					reg = <0x03>;
					remote-endpoint = <0x56>;
					phandle = <0x04>;
				};

				endpoint@4 {
					reg = <0x04>;
					remote-endpoint = <0x57>;
					phandle = <0x08>;
				};
			};
		};

		sram@900000 {
			compatible = "mmio-sram";
			reg = <0x900000 0x40000>;
			ranges = <0x00 0x900000 0x40000>;
			#address-cells = <0x01>;
			#size-cells = <0x01>;
			clocks = <0x02 0x8e>;
			phandle = <0x18>;
		};

		sata@2200000 {
			compatible = "fsl,imx6q-ahci";
			reg = <0x2200000 0x4000>;
			interrupts = <0x00 0x27 0x04>;
			clocks = <0x02 0x9a 0x02 0xbb 0x02 0x69>;
			clock-names = "sata", "sata_ref", "ahb";
			status = "okay";
		};

		gpu@2204000 {
			compatible = "vivante,gc";
			reg = <0x2204000 0x4000>;
			interrupts = <0x00 0x0b 0x04>;
			clocks = <0x02 0x8f 0x02 0x79>;
			clock-names = "bus", "core";
			power-domains = <0x12>;
			#cooling-cells = <0x02>;
		};

		ipu@2800000 {
			#address-cells = <0x01>;
			#size-cells = <0x00>;
			compatible = "fsl,imx6q-ipu";
			reg = <0x2800000 0x400000>;
			interrupts = <0x00 0x08 0x04 0x00 0x07 0x04>;
			clocks = <0x02 0x85 0x02 0x86 0x02 0x89>;
			clock-names = "bus", "di0", "di1";
			resets = <0x17 0x04>;

			port@0 {
				reg = <0x00>;
				phandle = <0x68>;

				endpoint {
					remote-endpoint = <0x58>;
					phandle = <0x46>;
				};
			};

			port@1 {
				reg = <0x01>;
				phandle = <0x69>;

				endpoint {
					remote-endpoint = <0x59>;
					phandle = <0x23>;
				};
			};

			port@2 {
				#address-cells = <0x01>;
				#size-cells = <0x00>;
				reg = <0x02>;
				phandle = <0x6c>;

				endpoint@0 {
					reg = <0x00>;
				};

				endpoint@1 {
					reg = <0x01>;
					remote-endpoint = <0x5a>;
					phandle = <0x10>;
				};

				endpoint@2 {
					reg = <0x02>;
					remote-endpoint = <0x5b>;
					phandle = <0x4b>;
				};

				endpoint@3 {
					reg = <0x03>;
					remote-endpoint = <0x5c>;
					phandle = <0x05>;
				};

				endpoint@4 {
					reg = <0x04>;
					remote-endpoint = <0x5d>;
					phandle = <0x09>;
				};
			};

			port@3 {
				#address-cells = <0x01>;
				#size-cells = <0x00>;
				reg = <0x03>;
				phandle = <0x6d>;

				endpoint@1 {
					reg = <0x01>;
					remote-endpoint = <0x5e>;
					phandle = <0x11>;
				};

				endpoint@2 {
					reg = <0x02>;
					remote-endpoint = <0x5f>;
					phandle = <0x4c>;
				};

				endpoint@3 {
					reg = <0x03>;
					remote-endpoint = <0x60>;
					phandle = <0x06>;
				};

				endpoint@4 {
					reg = <0x04>;
					remote-endpoint = <0x61>;
					phandle = <0x0a>;
				};
			};
		};
	};

	cpus {
		#address-cells = <0x01>;
		#size-cells = <0x00>;

		cpu@0 {
			compatible = "arm,cortex-a9";
			device_type = "cpu";
			reg = <0x00>;
			next-level-cache = <0x62>;
			operating-points = <0x124f80 0x137478 0xf32a0 0x1312d0 0xd0020 0x1312d0 0xc15c0 0x11edd8 0x60ae0 0xee098>;
			fsl,soc-operating-points = <0x124f80 0x137478 0xf32a0 0x1312d0 0xd0020 0x1312d0 0xc15c0 0x11edd8 0x60ae0 0x11edd8>;
			clock-latency = <0xee6c>;
			#cooling-cells = <0x02>;
			clocks = <0x02 0x68 0x02 0x06 0x02 0x10 0x02 0x11 0x02 0xaa>;
			clock-names = "arm", "pll2_pfd2_396m", "step", "pll1_sw", "pll1_sys";
			arm-supply = <0x63>;
			pu-supply = <0x1e>;
			soc-supply = <0x64>;
			nvmem-cells = <0x65>;
			nvmem-cell-names = "speed_grade";
		};

		cpu@1 {
			compatible = "arm,cortex-a9";
			device_type = "cpu";
			reg = <0x01>;
			next-level-cache = <0x62>;
			operating-points = <0x124f80 0x137478 0xf32a0 0x1312d0 0xd0020 0x1312d0 0xc15c0 0x11edd8 0x60ae0 0xee098>;
			fsl,soc-operating-points = <0x124f80 0x137478 0xf32a0 0x1312d0 0xd0020 0x1312d0 0xc15c0 0x11edd8 0x60ae0 0x11edd8>;
			clock-latency = <0xee6c>;
			#cooling-cells = <0x02>;
			clocks = <0x02 0x68 0x02 0x06 0x02 0x10 0x02 0x11 0x02 0xaa>;
			clock-names = "arm", "pll2_pfd2_396m", "step", "pll1_sw", "pll1_sys";
			arm-supply = <0x63>;
			pu-supply = <0x1e>;
			soc-supply = <0x64>;
		};

		cpu@2 {
			compatible = "arm,cortex-a9";
			device_type = "cpu";
			reg = <0x02>;
			next-level-cache = <0x62>;
			operating-points = <0x124f80 0x137478 0xf32a0 0x1312d0 0xd0020 0x1312d0 0xc15c0 0x11edd8 0x60ae0 0xee098>;
			fsl,soc-operating-points = <0x124f80 0x137478 0xf32a0 0x1312d0 0xd0020 0x1312d0 0xc15c0 0x11edd8 0x60ae0 0x11edd8>;
			clock-latency = <0xee6c>;
			#cooling-cells = <0x02>;
			clocks = <0x02 0x68 0x02 0x06 0x02 0x10 0x02 0x11 0x02 0xaa>;
			clock-names = "arm", "pll2_pfd2_396m", "step", "pll1_sw", "pll1_sys";
			arm-supply = <0x63>;
			pu-supply = <0x1e>;
			soc-supply = <0x64>;
		};

		cpu@3 {
			compatible = "arm,cortex-a9";
			device_type = "cpu";
			reg = <0x03>;
			next-level-cache = <0x62>;
			operating-points = <0x124f80 0x137478 0xf32a0 0x1312d0 0xd0020 0x1312d0 0xc15c0 0x11edd8 0x60ae0 0xee098>;
			fsl,soc-operating-points = <0x124f80 0x137478 0xf32a0 0x1312d0 0xd0020 0x1312d0 0xc15c0 0x11edd8 0x60ae0 0x11edd8>;
			clock-latency = <0xee6c>;
			#cooling-cells = <0x02>;
			clocks = <0x02 0x68 0x02 0x06 0x02 0x10 0x02 0x11 0x02 0xaa>;
			clock-names = "arm", "pll2_pfd2_396m", "step", "pll1_sw", "pll1_sys";
			arm-supply = <0x63>;
			pu-supply = <0x1e>;
			soc-supply = <0x64>;
		};
	};

	capture-subsystem {
		compatible = "fsl,imx-capture-subsystem";
		ports = <0x66 0x67 0x68 0x69>;
	};

	display-subsystem {
		compatible = "fsl,imx-display-subsystem";
		ports = <0x6a 0x6b 0x6c 0x6d>;
	};

	sound {
		compatible = "fsl,imx6-wandboard-sgtl5000", "fsl,imx-audio-sgtl5000";
		model = "imx6-wandboard-sgtl5000";
		ssi-controller = <0x6e>;
		audio-codec = <0x6f>;
		audio-routing = "MIC_IN", "Mic Jack", "Mic Jack", "Mic Bias", "Headphone Jack", "HP_OUT";
		mux-int-port = <0x01>;
		mux-ext-port = <0x03>;
	};

	sound-spdif {
		compatible = "fsl,imx-audio-spdif";
		model = "imx-spdif";
		spdif-controller = <0x70>;
		spdif-out;
	};

	regulator-1p5v {
		compatible = "regulator-fixed";
		regulator-name = "1P5V";
		regulator-min-microvolt = <0x16e360>;
		regulator-max-microvolt = <0x16e360>;
		regulator-always-on;
		phandle = <0x40>;
	};

	regulator-1p8v {
		compatible = "regulator-fixed";
		regulator-name = "1P8V";
		regulator-min-microvolt = <0x1b7740>;
		regulator-max-microvolt = <0x1b7740>;
		regulator-always-on;
		phandle = <0x3e>;
	};

	regulator-2p8v {
		compatible = "regulator-fixed";
		regulator-name = "2P8V";
		regulator-min-microvolt = <0x2ab980>;
		regulator-max-microvolt = <0x2ab980>;
		regulator-always-on;
		phandle = <0x3f>;
	};

	regulator-2p5v {
		compatible = "regulator-fixed";
		regulator-name = "2P5V";
		regulator-min-microvolt = <0x2625a0>;
		regulator-max-microvolt = <0x2625a0>;
		regulator-always-on;
		phandle = <0x3b>;
	};

	regulator-3p3v {
		compatible = "regulator-fixed";
		regulator-name = "3P3V";
		regulator-min-microvolt = <0x325aa0>;
		regulator-max-microvolt = <0x325aa0>;
		regulator-always-on;
		phandle = <0x3c>;
	};

	regulator-usbotgvbus {
		compatible = "regulator-fixed";
		regulator-name = "usb_otg_vbus";
		regulator-min-microvolt = <0x4c4b40>;
		regulator-max-microvolt = <0x4c4b40>;
		pinctrl-names = "default";
		pinctrl-0 = <0x71>;
		gpio = <0x2f 0x16 0x01>;
		phandle = <0x27>;
	};

	regulator-eth-phy {
		compatible = "regulator-fixed";
		regulator-name = "ETH_PHY";
		regulator-min-microvolt = <0x325aa0>;
		regulator-max-microvolt = <0x325aa0>;
		gpio = <0x72 0x0d 0x01>;
		phandle = <0x30>;
	};

	memory@10000000 {
		device_type = "memory";
		reg = <0x10000000 0x80000000>;
	};
};
